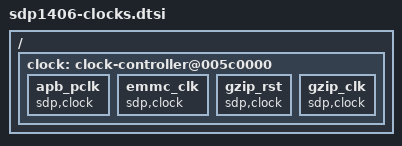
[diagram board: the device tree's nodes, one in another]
/*
 * Copyright (C) 2014 Samsung Electronics Co.Ltd
 *
 * This program is free software; you can redistribute it and/or modify
 * it under the terms of the GNU General Public License version 2 as
 * published by the Free Software Foundation.
 */

/ {
	clock: clock-controller@005c0000 {
		apb_pclk: apb_pclk {
			sdp,clock;
			#clock-cells = <0>;
		};
		emmc_clk: emmc_clk {
			sdp,clock;
			#clock-cells = <0>;
		};
		gzip_rst: gzip_rst {
			sdp,clock;
			#clock-cells = <0>;
		};			
		gzip_clk: gzip_clk {
			sdp,clock;
			#clock-cells = <0>;
		};			
	};
};

